// GENERATED by tools/gen_dbc.py from firmware/common/protocol/include/proto_id.h -- DO NOT EDIT BY HAND.

VERSION "can_distributed v1.0"

NS_ :

BS_:

BU_: MASTER NODE ALL_NODES

BA_DEF_ BU_ "GenMsgCycleTime" INT 0 65535;

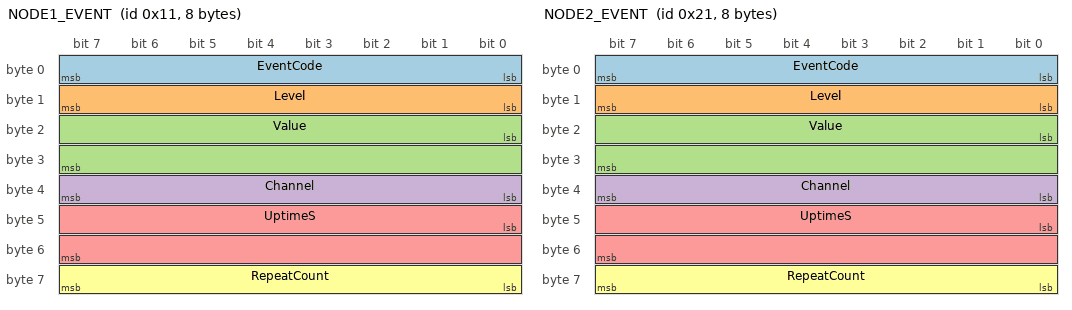
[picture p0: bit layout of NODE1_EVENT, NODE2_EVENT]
BO_ 17 NODE1_EVENT: 8 NODE
 SG_ EventCode : 0|8@1+ (1,0) [0|255] "" MASTER  // see VAL_ table
 SG_ Level : 8|8@1+ (1,0) [0|255] "" MASTER  // 0=info 1=warning 2=critical
 SG_ Value : 16|16@1- (1,0) [-32768|32767] "" MASTER  // trigger value; unit depends on EventCode (0.1 degC / lux / mA)
 SG_ Channel : 32|8@1+ (1,0) [0|255] "" MASTER  // related channel; 0 = not applicable
 SG_ UptimeS : 40|16@1+ (1,0) [0|65535] "s" MASTER  // node uptime low 16 bits, for event ordering (not wall-clock)
 SG_ RepeatCount : 56|8@1+ (1,0) [0|255] "" MASTER  // repeats since last report; saturates at 255 (storm suppression)

BO_ 33 NODE2_EVENT: 8 NODE
 SG_ EventCode : 0|8@1+ (1,0) [0|255] "" MASTER  // see VAL_ table
 SG_ Level : 8|8@1+ (1,0) [0|255] "" MASTER  // 0=info 1=warning 2=critical
 SG_ Value : 16|16@1- (1,0) [-32768|32767] "" MASTER  // trigger value; unit depends on EventCode (0.1 degC / lux / mA)
 SG_ Channel : 32|8@1+ (1,0) [0|255] "" MASTER  // related channel; 0 = not applicable
 SG_ UptimeS : 40|16@1+ (1,0) [0|65535] "s" MASTER  // node uptime low 16 bits, for event ordering (not wall-clock)
 SG_ RepeatCount : 56|8@1+ (1,0) [0|255] "" MASTER  // repeats since last report; saturates at 255 (storm suppression)

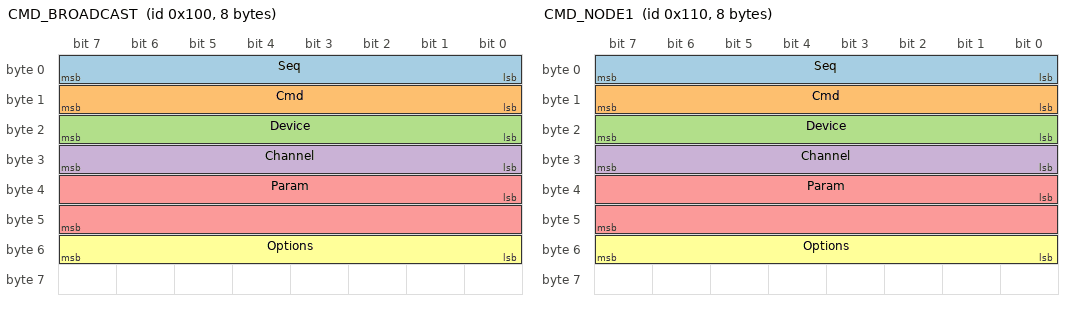
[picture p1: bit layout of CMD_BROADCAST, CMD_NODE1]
BO_ 256 CMD_BROADCAST: 8 MASTER
 SG_ Seq : 0|8@1+ (1,0) [0|255] "" ALL_NODES  // command sequence; per-channel counter (broadcast vs unicast)
 SG_ Cmd : 8|8@1+ (1,0) [0|255] "" ALL_NODES  // see VAL_ table
 SG_ Device : 16|8@1+ (1,0) [0|255] "" ALL_NODES  // 0=motor 1=servo 2=buzzer 3=system
 SG_ Channel : 24|8@1+ (1,0) [0|255] "" ALL_NODES  // channel / sub-index, meaning by Device
 SG_ Param : 32|16@1- (1,0) [-32768|32767] "" ALL_NODES  // motor/buzzer 0..1000, servo 0..180; out of range is rejected
 SG_ Options : 48|8@1+ (1,0) [0|255] "" ALL_NODES  // reserved, send 0

BO_ 272 CMD_NODE1: 8 MASTER
 SG_ Seq : 0|8@1+ (1,0) [0|255] "" NODE  // command sequence; per-channel counter (broadcast vs unicast)
 SG_ Cmd : 8|8@1+ (1,0) [0|255] "" NODE  // see VAL_ table
 SG_ Device : 16|8@1+ (1,0) [0|255] "" NODE  // 0=motor 1=servo 2=buzzer 3=system
 SG_ Channel : 24|8@1+ (1,0) [0|255] "" NODE  // channel / sub-index, meaning by Device
 SG_ Param : 32|16@1- (1,0) [-32768|32767] "" NODE  // motor/buzzer 0..1000, servo 0..180; out of range is rejected
 SG_ Options : 48|8@1+ (1,0) [0|255] "" NODE  // reserved, send 0

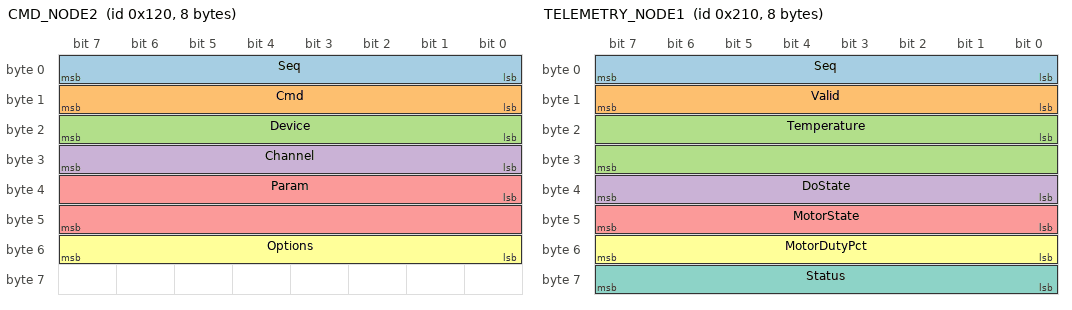
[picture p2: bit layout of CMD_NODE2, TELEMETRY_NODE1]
BO_ 288 CMD_NODE2: 8 MASTER
 SG_ Seq : 0|8@1+ (1,0) [0|255] "" NODE  // command sequence; per-channel counter (broadcast vs unicast)
 SG_ Cmd : 8|8@1+ (1,0) [0|255] "" NODE  // see VAL_ table
 SG_ Device : 16|8@1+ (1,0) [0|255] "" NODE  // 0=motor 1=servo 2=buzzer 3=system
 SG_ Channel : 24|8@1+ (1,0) [0|255] "" NODE  // channel / sub-index, meaning by Device
 SG_ Param : 32|16@1- (1,0) [-32768|32767] "" NODE  // motor/buzzer 0..1000, servo 0..180; out of range is rejected
 SG_ Options : 48|8@1+ (1,0) [0|255] "" NODE  // reserved, send 0

BO_ 528 TELEMETRY_NODE1: 8 NODE
 SG_ Seq : 0|8@1+ (1,0) [0|255] "" MASTER  // telemetry sequence; gap = dropped frame
 SG_ Valid : 8|8@1+ (1,0) [0|255] "" MASTER  // bit0=temperature valid, bit1=DO valid, bit2=current valid (needs hardware)
 SG_ Temperature : 16|16@1- (0.1,0) [-32768|32767] "degC" MASTER  // signed; factor 0.1 -> raw 285 means 28.5 degC
 SG_ DoState : 32|8@1+ (1,0) [0|255] "" MASTER  // thermistor digital output
 SG_ MotorState : 40|8@1+ (1,0) [0|255] "" MASTER  // 0=stop 1=forward 2=reverse 3=brake
 SG_ MotorDutyPct : 48|8@1+ (1,0) [0|255] "%" MASTER  // current PWM duty 0..100
 SG_ Status : 56|8@1+ (1,0) [0|255] "" MASTER  // bit0=stall (needs current sampling), bit1=over-temp, bit2=sensor fault

BA_ "GenMsgCycleTime" BO_ 528 1000;

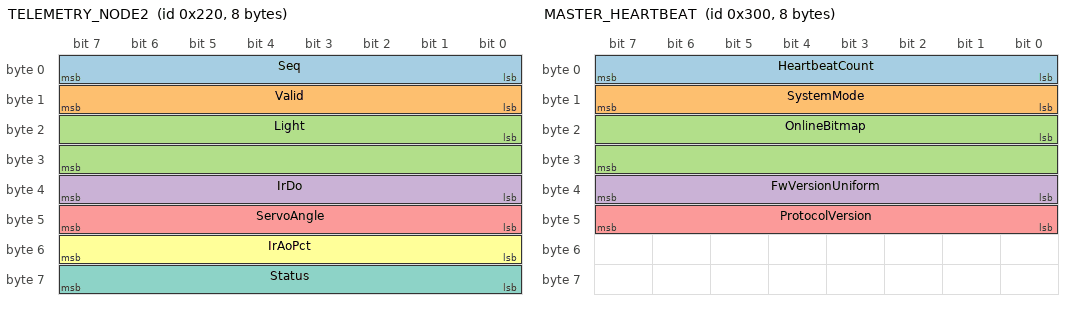
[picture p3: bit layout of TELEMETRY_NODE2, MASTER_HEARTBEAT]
BO_ 544 TELEMETRY_NODE2: 8 NODE
 SG_ Seq : 0|8@1+ (1,0) [0|255] "" MASTER  // telemetry sequence
 SG_ Valid : 8|8@1+ (1,0) [0|255] "" MASTER  // bit0=light valid, bit1=IR DO valid, bit2=IR AO valid
 SG_ Light : 16|16@1+ (1,0) [0|65535] "lux" MASTER  // illuminance in lux (BH1750 recommended)
 SG_ IrDo : 32|8@1+ (1,0) [0|255] "" MASTER  // IR digital output
 SG_ ServoAngle : 40|8@1+ (1,0) [0|255] "deg" MASTER  // 0..180, out of range is rejected
 SG_ IrAoPct : 48|8@1+ (1,0) [0|255] "%" MASTER  // IR analog normalised 0..100
 SG_ Status : 56|8@1+ (1,0) [0|255] "" MASTER  // reserved / undefined until hardware is fixed

BA_ "GenMsgCycleTime" BO_ 544 1000;

BO_ 768 MASTER_HEARTBEAT: 8 MASTER
 SG_ HeartbeatCount : 0|8@1+ (1,0) [0|255] "" ALL_NODES  // wraps; frozen value means master stuck
 SG_ SystemMode : 8|8@1+ (1,0) [0|255] "" ALL_NODES  // reserved, send 0
 SG_ OnlineBitmap : 16|16@1+ (1,0) [0|65535] "" ALL_NODES  // bit N set = node N online (bit1 = node1)
 SG_ FwVersionUniform : 32|8@1+ (1,0) [0|255] "" ALL_NODES  // 0 = all nodes consistent
 SG_ ProtocolVersion : 40|8@1+ (1,0) [0|255] "" ALL_NODES  // protocol version, separate from fw

BA_ "GenMsgCycleTime" BO_ 768 1000;

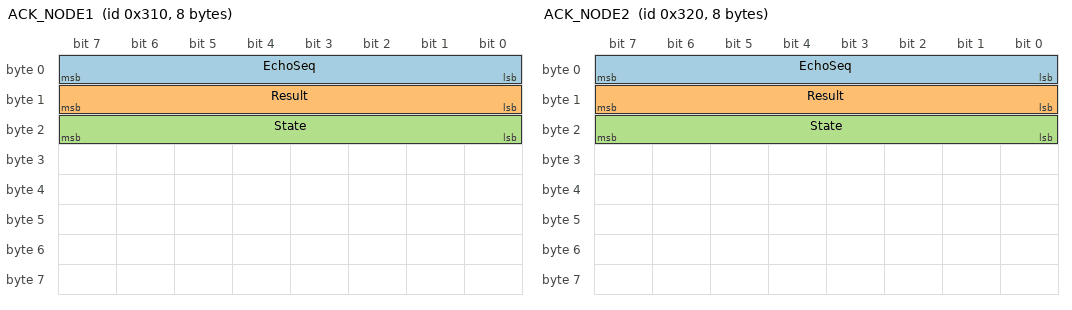
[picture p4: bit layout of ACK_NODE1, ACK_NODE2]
BO_ 784 ACK_NODE1: 8 NODE
 SG_ EchoSeq : 0|8@1+ (1,0) [0|255] "" MASTER  // echoes the command Seq
 SG_ Result : 8|8@1+ (1,0) [0|255] "" MASTER  // 0=success, otherwise protocol error code
 SG_ State : 16|8@1+ (1,0) [0|255] "" MASTER  // device state after execution

BO_ 800 ACK_NODE2: 8 NODE
 SG_ EchoSeq : 0|8@1+ (1,0) [0|255] "" MASTER  // echoes the command Seq
 SG_ Result : 8|8@1+ (1,0) [0|255] "" MASTER  // 0=success, otherwise protocol error code
 SG_ State : 16|8@1+ (1,0) [0|255] "" MASTER  // device state after execution

VAL_ 17 EventCode 1 "OVER_TEMP" 2 "TEMP_LIMIT" 3 "IR_TRIGGER" 4 "LIGHT_LIMIT" 5 "STALL_NEEDS_CURRENT_HW" 6 "SENSOR_FAULT" ;
VAL_ 17 Level 0 "INFO" 1 "WARNING" 2 "CRITICAL" ;
VAL_ 33 EventCode 1 "OVER_TEMP" 2 "TEMP_LIMIT" 3 "IR_TRIGGER" 4 "LIGHT_LIMIT" 5 "STALL_NEEDS_CURRENT_HW" 6 "SENSOR_FAULT" ;
VAL_ 33 Level 0 "INFO" 1 "WARNING" 2 "CRITICAL" ;
VAL_ 256 Cmd 1 "SET" 2 "STOP" 3 "RESET" 4 "QUERY" ;
VAL_ 256 Device 0 "MOTOR" 1 "SERVO" 2 "BUZZER" 3 "SYSTEM" ;
VAL_ 272 Cmd 1 "SET" 2 "STOP" 3 "RESET" 4 "QUERY" ;
VAL_ 272 Device 0 "MOTOR" 1 "SERVO" 2 "BUZZER" 3 "SYSTEM" ;
VAL_ 288 Cmd 1 "SET" 2 "STOP" 3 "RESET" 4 "QUERY" ;
VAL_ 288 Device 0 "MOTOR" 1 "SERVO" 2 "BUZZER" 3 "SYSTEM" ;
VAL_ 528 Valid 0 "temperature" 1 "do_state" 2 "current" ;
VAL_ 528 MotorState 0 "STOP" 1 "FORWARD" 2 "REVERSE" 3 "BRAKE" ;
VAL_ 544 Valid 0 "temperature" 1 "do_state" 2 "current" ;
VAL_ 784 Result 0 "OK" 1 "ERR_LEN" 2 "ERR_ID" 3 "ERR_NODE" 4 "ERR_RANGE" 5 "ERR_VALUE" 6 "ERR_STATE" 7 "ERR_BUSY" 8 "ERR_CRC" 9 "ERR_UNSUPPORTED" ;
VAL_ 800 Result 0 "OK" 1 "ERR_LEN" 2 "ERR_ID" 3 "ERR_NODE" 4 "ERR_RANGE" 5 "ERR_VALUE" 6 "ERR_STATE" 7 "ERR_BUSY" 8 "ERR_CRC" 9 "ERR_UNSUPPORTED" ;

BA_DEF_ "BusType" STRING ;
BA_DEF_ "ProtocolVersion" INT 0 255;
BA_DEF_DEF_ "GenMsgCycleTime" 0;
BA_DEF_DEF_ "BusType" "CAN";
BA_DEF_DEF_ "ProtocolVersion" 1;
